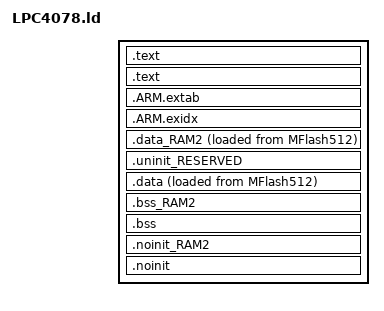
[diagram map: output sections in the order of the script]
/*
 * GENERATED FILE - DO NOT EDIT
 * (c) Code Red Technologies Ltd, 2008-2013
 * (c) NXP Semiconductors 2013-2018
 * Generated linker script file for LPC4078
 * Created from linkscript.ldt by FMCreateLinkLibraries
 * Using Freemarker v2.3.23
 * LPCXpresso v8.2.2 [Build 650] [2016-09-09]  on Jun 3, 2018 12:50:46 AM
 */

ENTRY(ResetIsr)

SECTIONS
{
    /* MAIN TEXT SECTION */
    .text : ALIGN(4)
    {
        FILL(0xff)
        __vectors_start__ = ABSOLUTE(.) ;
        KEEP(*(.isr_vector))
        /* Global Section Table */
        . = ALIGN(4) ;
        section_table_start = .;
        data_section_table = .;
        LONG(LOADADDR(.data));
        LONG(    ADDR(.data));
        LONG(  SIZEOF(.data));
        LONG(LOADADDR(.data_RAM2));
        LONG(    ADDR(.data_RAM2));
        LONG(  SIZEOF(.data_RAM2));
        data_section_table_end = .;
        bss_section_table = .;
        LONG(    ADDR(.bss));
        LONG(  SIZEOF(.bss));
        LONG(    ADDR(.bss_RAM2));
        LONG(  SIZEOF(.bss_RAM2));
        bss_section_table_end = .;
        section_table_end = . ;
	    /* End of Global Section Table */

        *(.after_vectors*)

        /* Code Read Protection data */
        . = 0x000002FC ;
        PROVIDE(__CRP_WORD_START__ = .) ;
        KEEP(*(.crp))
        PROVIDE(__CRP_WORD_END__ = .) ;
        ASSERT(!(__CRP_WORD_START__ == __CRP_WORD_END__), "Linker CRP Enabled, but no CRP_WORD provided within application");
        /* End of Code Read Protection */

        /* C++ constructors etc */
		. = ALIGN(4);
		KEEP(*(.init))

		. = ALIGN(4);
		__preinit_array_start = .;
		KEEP (*(.preinit_array))
		__preinit_array_end = .;

		. = ALIGN(4);
		__init_array_start = .;
		KEEP (*(SORT(.init_array.*)))
		KEEP (*(.init_array))
		__init_array_end = .;

		KEEP(*(.fini));

		. = ALIGN(4);
		KEEP (*crtbegin.o(.ctors))
		KEEP (*(EXCLUDE_FILE (*crtend.o) .ctors))
		KEEP (*(SORT(.ctors.*)))
		KEEP (*crtend.o(.ctors))

		. = ALIGN(4);
		KEEP (*crtbegin.o(.dtors))
		KEEP (*(EXCLUDE_FILE (*crtend.o) .dtors))
		KEEP (*(SORT(.dtors.*)))
		KEEP (*crtend.o(.dtors))
        /* End C++ */
    } >MFlash512

    .text : ALIGN(4)
    {
        *(.text*)
        *(.rodata .rodata.* .constdata .constdata.*)
        . = ALIGN(4);
    } > MFlash512
    /*
     * for exception handling/unwind - some Newlib functions (in common
     * with C++ and STDC++) use this.
     */
    .ARM.extab : ALIGN(4)
    {
        *(.ARM.extab* .gnu.linkonce.armextab.*)
    } > MFlash512
    __exidx_start = .;

    .ARM.exidx : ALIGN(4)
    {
        *(.ARM.exidx* .gnu.linkonce.armexidx.*)
    } > MFlash512
    __exidx_end = .;

    _etext = .;

    /* DATA section for RamPeriph32 */
    .data_RAM2 : ALIGN(4)
    {
        FILL(0xff)
        PROVIDE(__start_data_RAM2 = .) ;
        *(.ramfunc.$RAM2)
        *(.ramfunc.$RamPeriph32)
        *(.data.$RAM2*)
        *(.data.$RamPeriph32*)
        . = ALIGN(4) ;
        PROVIDE(__end_data_RAM2 = .) ;
     } > RamPeriph32 AT>MFlash512

    /* MAIN DATA SECTION */
    .uninit_RESERVED : ALIGN(4)
    {
        KEEP(*(.bss.$RESERVED*))
        . = ALIGN(4) ;
        _end_uninit_RESERVED = .;
    } > RamLoc64
    /* Main DATA section (RamLoc64) */
    .data : ALIGN(4)
    {
       FILL(0xff)
       _data = . ;
       *(vtable)
       *(.ramfunc*)
       *(.data*)
       . = ALIGN(4) ;
       _edata = . ;
    } > RamLoc64 AT>MFlash512
    /* BSS section for RamPeriph32 */
    .bss_RAM2 : ALIGN(4)
    {
       PROVIDE(__start_bss_RAM2 = .) ;
       *(.bss.$RAM2*)
       *(.bss.$RamPeriph32*)
       . = ALIGN (. != 0 ? 4 : 1) ; /* avoid empty segment */
       PROVIDE(__end_bss_RAM2 = .) ;
    } > RamPeriph32
    /* MAIN BSS SECTION */
    .bss : ALIGN(4)
    {
        _bss = .;
        *(.bss*)
        *(COMMON)
        . = ALIGN(4) ;
        _ebss = .;
        PROVIDE(end = .);
    } > RamLoc64
    /* NOINIT section for RamPeriph32 */
    .noinit_RAM2 (NOLOAD) : ALIGN(4)
    {
       *(.noinit.$RAM2*)
       *(.noinit.$RamPeriph32*)
       . = ALIGN(4) ;
    } > RamPeriph32
    /* DEFAULT NOINIT SECTION */
    .noinit (NOLOAD): ALIGN(4)
    {
        _noinit = .;
        *(.noinit*)
         . = ALIGN(4) ;
        _end_noinit = .;
    } > RamLoc64

    PROVIDE(heap = DEFINED(__user_heap_base) ? __user_heap_base : .);
    PROVIDE(StackTop = DEFINED(__user_stack_top) ? __user_stack_top : __top_RamLoc64 - 0);

    /* ## Create checksum value (used in startup) ## */
    PROVIDE(ValidUserCodeChecksum = 0 -
                                       (StackTop
                                       + (ResetIsr + 1)
                                       + (NmiHandler + 1)
                                       + (HardFaultHandler + 1)
                                       + (( DEFINED(MemManageHandler) ? MemManageHandler : 0 ) + 1)   /* MemManageHandler may not be defined */
                                       + (( DEFINED(BusFaultHandler) ? BusFaultHandler : 0 ) + 1)     /* BusFaultHandler may not be defined */
                                       + (( DEFINED(UsageFaultHandler) ? UsageFaultHandler : 0 ) + 1) /* UsageFaultHandler may not be defined */
                                       ) );
}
